VERSION ""

NS_ :

BS_:

BU_: Vector__XXX

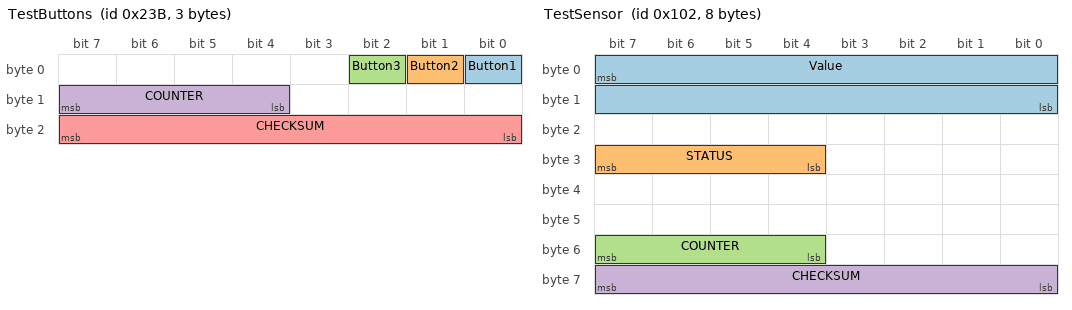
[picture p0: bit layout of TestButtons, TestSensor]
BO_ 571 TestButtons: 3 Vector__XXX
 SG_ Button1 : 0|1@1+ (1,0) [0|1] "" Vector__XXX
 SG_ Button2 : 1|1@1+ (1,0) [0|1] "" Vector__XXX
 SG_ Button3 : 2|1@1+ (1,0) [0|1] "" Vector__XXX
 SG_ COUNTER : 15|4@0+ (1,0) [0|15] "" Vector__XXX
 SG_ CHECKSUM : 23|8@0+ (1,0) [0|255] "" Vector__XXX

BO_ 258 TestSensor: 8 Vector__XXX
 SG_ Value : 7|16@0+ (1,0) [0|65535] "" Vector__XXX
 SG_ STATUS : 31|4@0+ (1,0) [0|15] "" Vector__XXX
 SG_ COUNTER : 55|4@0+ (1,0) [0|15] "" Vector__XXX
 SG_ CHECKSUM : 63|8@0+ (1,0) [0|255] "" Vector__XXX
